# S32K142_M4 register map
Vendor: NXP Semiconductors; File version: 1.0
CPU: CM4 r0p1, little endian, MPU, FPU, VTOR, 4 interrupt priority bits
Registers are 32-bit, read-write, reset 0x0 unless marked. A register's access mark holds for its fields unless they carry their own. Offsets are from the block's base; [hi:lo] are bit positions; {n}, {i} and the like mark numbered series.

## CTI — D_IP_CTI_SYN
Base 0x00000000
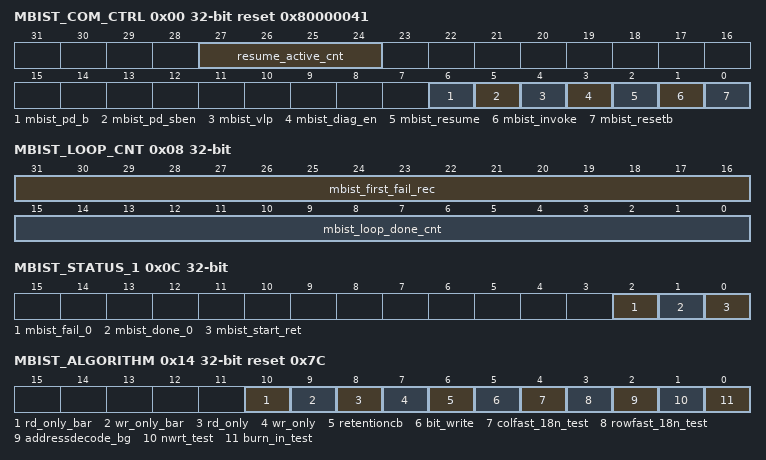
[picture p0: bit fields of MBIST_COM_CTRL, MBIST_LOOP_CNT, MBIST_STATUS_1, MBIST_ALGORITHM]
0x00 MBIST_COM_CTRL reset 0x80000041 — RAMBIST COMMON CONTROL Register
  [27:24] resume_active_cnt — To define the resume active time frame
    0=mbist_resume (MBIST_COM_CTRL[2] active time frame will last 3 IPS clocks; 1=mbist_resume (MBIST_COM_CTRL[2] active time frame will last 6 IPS clocks; 2=mbist_resume (MBIST_COM_CTRL[2] active time frame will last 10 IPS clocks; 3=mbist_resume (MBIST_COM_CTRL[2] active time frame will last 14 IPS clocks; 4=mbist_resume (MBIST_COM_CTRL[2] active time frame will last 18 IPS clocks; 5=mbist_resume (MBIST_COM_CTRL[2] active time frame will last 22 IPS clocks; 6=mbist_resume (MBIST_COM_CTRL[2] active time frame will last 26 IPS clocks; 7=mbist_resume (MBIST_COM_CTRL[2] active time frame will last 30 IPS clocks; 8=if resume_active_cnt[3] =1, resume count will has no effect to mbist_resume
  [6] mbist_pd_b — MBIST power down mode enable
  [5] mbist_pd_sben — MBIST source bias enable
  [4] mbist_vlp — MBIST VLP enable
  [3] mbist_diag_en — MBIST Diagnose Enable
  [2] mbist_resume — MBIST Invoke
  [1] mbist_invoke
  [0] mbist_resetb — MBIST Reset
0x04 MBIST_SEL — RAMBIST Selection Register
  [0] mbist_select0 — MBIST Wrapper Select
0x08 MBIST_LOOP_CNT — RAMBIST Loop Counter Register
  [31:16] mbist_first_fail_rec — MBIST first fail record
  [15:0] mbist_loop_done_cnt — MBIST loop done counter
0x0C MBIST_STATUS_1 ro — The First Group of MBIST Status Register
  [2] mbist_fail_0 — MBIST fail signal
  [1] mbist_done_0 — MBIST done signal
  [0] mbist_start_ret — MBIST start retention
0x10 MBIST_STATUS_2 ro — The Second Group of MBIST Status Register
0x14 MBIST_ALGORITHM reset 0x7C — RAMBIST Algorithm Register
  [10] rd_only_bar — For all bist enginee
  [9] wr_only_bar — For all bist enginee
  [8] rd_only — For all bist enginee
  [7] wr_only — For all bist enginee
  [6] retentioncb — For all bist enginee
  [5] bit_write — For all bist enginee
  [4] colfast_18n_test — For all bist enginee
  [3] rowfast_18n_test — For all bist enginee
  [2] addressdecode_bg — For all bist enginee
  [1] nwrt_test — For all bist enginee
  [0] burn_in_test — For all bist enginee
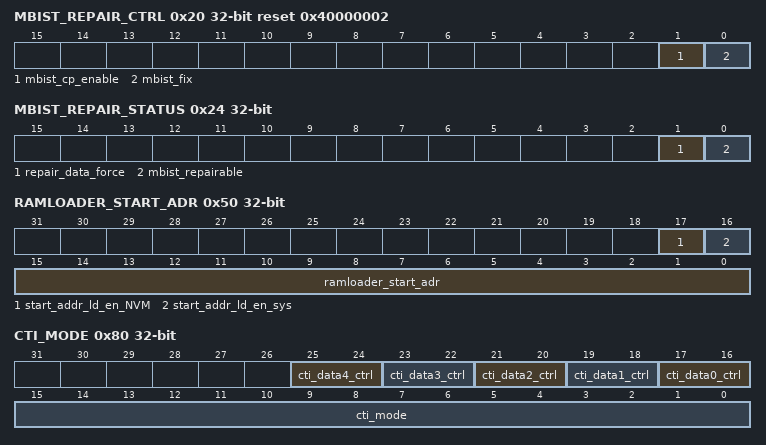
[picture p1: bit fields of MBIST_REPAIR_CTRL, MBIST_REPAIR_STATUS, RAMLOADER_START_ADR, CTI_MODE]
0x20 MBIST_REPAIR_CTRL reset 0x40000002 — RAMBIST Repair Control Register
  [1] mbist_cp_enable — MBIST Repair Source selection
    0=Repair source is from BIST controller; 1=Repair source is from SIM
  [0] mbist_fix — MBIST Repair Fix
    0=it allows the BISR to evaluate the repair abilit and generate a repair solution; 1=it does not allow the current solution container to be changed
0x24 MBIST_REPAIR_STATUS ro — RAMBIST REPAIR STATUS Register
  [1] repair_data_force — Indicate the repair data is avaliable, and tester can record
  [0] mbist_repairable — RAM repairable indicator signal
{0x24+4i} MBIST_REPAIR_INFO_{i} ro (i=1..8) — MBIST Repair Info Register
0x50 RAMLOADER_START_ADR — RAMLOADER START ADDRESS Register
  [17] start_addr_ld_en_NVM — Start address load enable
  [16] start_addr_ld_en_sys — Start address load enable
  [15:0] ramloader_start_adr
0x80 CTI_MODE
  [2n+17:2n+16] cti_data{n}_ctrl (n=0..4) — CTI DATA0 Control
    0=The IO of CTI_DATA{n} was safe, ibe=0 and obe=0; 1=The IO of CTI_DATA{n} was input, ibe=1 and obe=0; 2=The IO of CTI_DATA{n} was output, ibe=0 and obe=1; 3=The IO of CTI_DATA{n} was safe, ibe=0 and obe=0
  [15:0] cti_mode — CTI Sub-modes registers
    1=CTI Sub-mode1; 2=CTI Sub-mode2; 4=CTI Sub-mode3; 8=CTI Sub-mode4; 16=CTI Sub-mode5; 32=CTI Sub-mode6; 64=CTI Sub-mode7; 128=CTI Sub-mode8; 0x100=CTI Sub-mode9; 0x200=CTI Sub-mode10
0xC0 CTI_MIX_CTRL — CTI MIX ControlRegister
  [0] tstjtag_dsel — Test JTAG Deselect

## Notices in the file
Copyright 2016-2021 NXP
NXP Confidential. This software is owned or controlled by NXP and may only be
used strictly in accordance with the applicable license terms. By expressly
accepting such terms or by downloading, installing, activating and/or otherwise
using the software, you are agreeing that you have read, and that you agree to
comply with and are bound by, such license terms. If you do not agree to be
bound by the applicable license terms, then you may not retain, install,
activate or otherwise use the software. The production use license in
Section 2.3 is expressly granted for this software.
